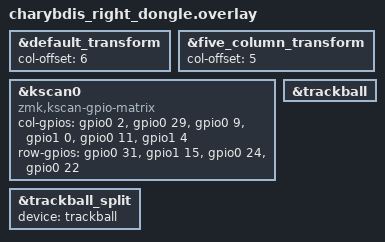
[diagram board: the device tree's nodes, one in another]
#include "../charybdis_common/charybdis.dtsi"
#include "../charybdis_trackball/charybdis_pmw3610.dtsi"
#include "../../config/trackball/charybdis_pointer.dtsi"


// The matrix transform is 6 columns over because the left half is 6 columns wide.
&default_transform {
	col-offset = <6>;
};

&five_column_transform {
	col-offset = <5>;
};

&kscan0 {
	compatible = "zmk,kscan-gpio-matrix";
	
	col-gpios
		= <&gpio0 2  (GPIO_ACTIVE_HIGH | GPIO_PULL_DOWN)>
		, <&gpio0 29 (GPIO_ACTIVE_HIGH | GPIO_PULL_DOWN)>
		, <&gpio0 9  (GPIO_ACTIVE_HIGH | GPIO_PULL_DOWN)>
		, <&gpio1 0  (GPIO_ACTIVE_HIGH | GPIO_PULL_DOWN)>
		, <&gpio0 11 (GPIO_ACTIVE_HIGH | GPIO_PULL_DOWN)>
		, <&gpio1 4  (GPIO_ACTIVE_HIGH | GPIO_PULL_DOWN)>
		;

	row-gpios
		= <&gpio0 31 GPIO_ACTIVE_HIGH>
		, <&gpio1 15 GPIO_ACTIVE_HIGH>
		, <&gpio0 24 GPIO_ACTIVE_HIGH>
		, <&gpio0 22 GPIO_ACTIVE_HIGH>
		;
};

&trackball {
  status = "okay";
};

/* Enable the trackball listener on the peripheral with the sensor */
&trackball_split {
  device = <&trackball>;
  status = "okay";
};
